# STM32WB05 register map
File version: 1.0
CPU: CM0+ r0p0, little endian, MPU, no FPU, 2 interrupt priority bits
Registers are 32-bit, read-write, reset 0x0 unless marked. A register's access mark holds for its fields unless they carry their own. Offsets are from the block's base; [hi:lo] are bit positions.

## USART
Base 0x41004000
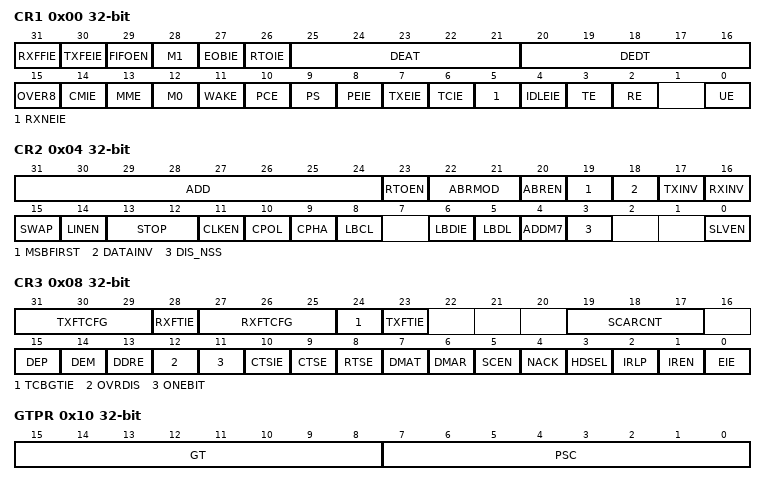
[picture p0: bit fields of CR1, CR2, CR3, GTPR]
0x00 CR1
  [31] RXFFIE — RXFFIE :RXFIFO Full interrupt enable This bit is set and cleared by software. -0: Interrupt is inhibited -1: An USART interrupt is generated when RXFF=1 in the USART_ISR register
    0=Disabled (Interrupt inhibited); 1=Enabled (USART interrupt generated when RXFF = 1 in the USART_ISR register)
  [30] TXFEIE — TXFEIE :TXFIFO empty interrupt enable This bit is set and cleared by software. -0: Interrupt is inhibited -1: An USART interrupt is generated when TXFE=1 in the USART_ISR register
    0=Disabled (Interrupt inhibited); 1=Enabled (USART interrupt generated when TXFE = 1 in the USART_ISR register)
  [29] FIFOEN — FIFOEN :FIFO mode enable This bit is set and cleared by software. -0: FIFO mode is disabled. -1: FIFO mode is enabled.
    0=Disabled (FIFO mode is disabled); 1=Enabled (FIFO mode is enabled)
  [28] M1 — Word length This bit, with bit 12 (M0) determine the word length. It is set or cleared by software. M[1:0] = 00: 1 Start bit, 8 Data bits, n Stop bit M[1:0] = 01: 1 Start bit, 9 Data bits, n Stop bit M[1:0] = 10: 1 Start bit, 7 Data bits, n Stop bit This bit can only be written when the USART is disabled (UE=0).s
    0=M0 (Use M0 to set the data bits); 1=Bit7 (1 start bit, 7 data bits, n stop bits)
  [27] EOBIE — EOBIE: End of Block interrupt enable This bit is set and cleared by software.
    0=Disabled (Interrupt is inhibited); 1=Enabled (A USART interrupt is generated when the EOBF flag is set in the ISR register)
  [26] RTOIE — RTOIE: Receiver timeout interrupt enable This bit is set and cleared by software. -0: Interrupt is inhibited -1: An USART interrupt is generated when the RTOF bit is set in the USART_ISR register
    0=Disabled (Interrupt is inhibited); 1=Enabled (An USART interrupt is generated when the RTOF bit is set in the ISR register)
  [25:21] DEAT — DEAT[4:0]: Driver Enable assertion time This 5-bit value defines the time between the activation of the DE (Driver Enable) signal and the beginning of the start bit. It is expressed in sample time units (1/8 or 1/16 bit time, depending on the oversampling rate). This bit field can only be written when the USART is disabled (UE=0).
  [20:16] DEDT — DEDT[4:0]: Driver Enable deassertion time This 5-bit value defines the time between the end of the last stop bit, in a transmitted message, and the de-activation of the DE (Driver Enable) signal. It is expressed in sample time units (1/8 or 1/16 bit time, depending on the oversampling rate). If the USART_TDR register is written during the DEDT time, the new data is transmitted only when the DEDT and DEAT times have both elapsed. This bit field can only be written when the USART is disabled (UE=0).
  [15] OVER8 — OVER8: Oversampling mode -0: Oversampling by 16 This bit can only be written when the USART is disabled (UE=0).
    0=Oversampling16 (Oversampling by 16); 1=Oversampling8 (Oversampling by 8)
  [14] CMIE — CMIE: Character match interrupt enable This bit is set and cleared by software. -0: Interrupt is inhibited -1: A USART interrupt is generated when the CMF bit is set in the USART_ISR register.
    0=Disabled (Interrupt is disabled); 1=Enabled (Interrupt is generated when the CMF bit is set in the ISR register)
  [13] MME — MME: Mute mode enable This bit activates the mute mode function of the USART. When set, the USART can switch between the active and mute modes, as defined by the WAKE bit. It is set and cleared by software. -0: Receiver in active mode permanently -1: Receiver can switch between mute mode and active mode
    0=Disabled (Receiver in active mode permanently); 1=Enabled (Receiver can switch between mute mode and active mode)
  [12] M0 — M0: Word length This bit, with bit 28 (M1) determine the word length. It is set or cleared by software. See Bit -28 (M1)description. This bit can only be written when the USART is disabled (UE=0).
    0=Bit8 (1 start bit, 8 data bits, n stop bits); 1=Bit9 (1 start bit, 9 data bits, n stop bits)
  [11] WAKE — WAKE: Receiver wakeup method This bit determines the USART wakeup method from Mute mode. It is set or cleared by software. -0: Idle line -1: Address mark This bit field can only be written when the USART is disabled (UE=0).
    0=Idle line; 1=Address mask
  [10] PCE — PCE: Parity control enable This bit selects the hardware parity control (generation and detection). When the parity control is enabled, the computed parity is inserted at the MSB position (9th bit if M=1; 8th bit if M=0) and parity is checked on the received data. This bit is set and cleared by software. Once it is set, PCE is active after the current byte (in reception and in transmission). -0: Parity control disabled -1: Parity control enabled This bit field can only be written when the USART is disabled (UE=0).
    0=Disabled (Parity control disabled); 1=Enabled (Parity control enabled)
  [9] PS — PS: Parity selection This bit selects the odd or even parity when the parity generation/detection is enabled (PCE bit set). It is set and cleared by software. The parity will be selected after the current byte. -0: Even parity -1: Odd parity This bit field can only be written when the USART is disabled (UE=0).
    0=Even parity; 1=Odd (Odd parity)
  [8] PEIE — PEIE: PE interrupt enable This bit is set and cleared by software. -0: Interrupt is inhibited -1: A USART interrupt is generated whenever PE=1 in the USART_ISR register
    0=Disabled (Interrupt is disabled); 1=Enabled (Interrupt is generated whenever PE=1 in the ISR register)
  [7] TXEIE — TXEIE/TXFNFIE: Transmit data regsiter empty/TXFIFO not full interrupt enable This bit is set and cleared by software. -0: Interrupt is inhibited -1: A USART interrupt is generated whenever TXE/TXFNF =1 in the USART_ISR register
    0=Disabled (Interrupt is disabled); 1=Enabled (Interrupt is generated whenever TXE=1 in the ISR register)
  [6] TCIE — TCIE: Transmission complete interrupt enable This bit is set and cleared by software. -0: Interrupt is inhibited -1: A USART interrupt is generated whenever TC=1 in the USART_ISR register
    0=Disabled (Interrupt is disabled); 1=Enabled (Interrupt is generated whenever TC=1 in the ISR register)
  [5] RXNEIE — RXNEIE/RXFNEIE: Receive data register not empty/RXFIFO not empty interrupt enable This bit is set and cleared by software. -0: Interrupt is inhibited -1: An USART interrupt is generated whenever ORE=1 or RXNE/RXFNE=1 in the USART_ISR register
    0=Disabled (Interrupt is disabled); 1=Enabled (Interrupt is generated whenever ORE=1 or RXNE=1 in the ISR register)
  [4] IDLEIE — IDLEIE: IDLE interrupt enable This bit is set and cleared by software. -0: Interrupt is inhibited -1: A USART interrupt is generated whenever IDLE=1 in the USART_ISR register
    0=Disabled (Interrupt is disabled); 1=Enabled (Interrupt is generated whenever IDLE=1 in the ISR register)
  [3] TE — TE: Transmitter enable This bit enables the transmitter. It is set and cleared by software. -0: Transmitter is disabled -1: Transmitter is enabled
    0=Disabled (Transmitter is disabled); 1=Enabled (Transmitter is enabled)
  [2] RE — RE: Receiver enable This bit enables the receiver. It is set and cleared by software. -0: Receiver is disabled -1: Receiver is enabled and begins searching for a start bit
    0=Disabled (Receiver is disabled); 1=Enabled (Receiver is enabled)
  [0] UE — UE: USART enable When this bit is cleared, the USART prescalers and outputs are stopped immediately, and current operations are discarded. The configuration of the USART is kept, but all the status flags, in the USART_ISR are reset. This bit is set and cleared by software. -0: USART prescaler and outputs disabled, low power mode -1: USART enabled
    0=Disabled (UART is disabled); 1=Enabled (UART is enabled)
0x04 CR2
  [31:24] ADD — ADD[7:0]: Address of the USART node This bit-field gives the address of the USART node or a character code to be recognized. This is used in multiprocessor communication during Mute mode or Stop mode, for wakeup with 7- bit address mark detection. The MSB of the character sent by the transmitter should be equal to 1. It may also be used for character detection during normal reception, Mute mode inactive (for example, end of block detection in ModBus protocol). In this case, the whole received character (8- bit) is compared to the ADD[7:0] value and CMF flag is set on match. This bit field can only be written when reception is disabled (RE = 0) or the USART is disabled (UE=0)
  [23] RTOEN — RTOEN: Receiver timeout enable This bit is set and cleared by software. -0: Receiver timeout feature disabled. -1: Receiver timeout feature enabled. When this feature is enabled, the RTOF flag in the USART_ISR register is set if the RX line is idle (no reception) for the duration programmed in the RTOR (receiver timeout register).
    0=Disabled (Receiver timeout feature disabled); 1=Enabled (Receiver timeout feature enabled)
  [22:21] ABRMOD — ABRMOD[1:0]: Auto baud rate mode These bits are set and cleared by software. -00: Measurement of the start bit is used to detect the baud rate. -01: Falling edge to falling edge measurement. (the received frame must start with a single bit = 1 -> Frame = Start10xxxxxx) -10: 0x7F frame detection. -11: 0x55 frame detection This bit field can only be written when ABREN = 0 or the USART is disabled (UE=0).
    0=Start (Measurement of the start bit is used to detect the baud rate); 1=Edge (Falling edge to falling edge measurement); 2=Frame7F (0x7F frame detection); 3=Frame55 (0x55 frame detection)
  [20] ABREN — ABREN: Auto baud rate enable This bit is set and cleared by software. -0: Auto baud rate detection is disabled. -1: Auto baud rate detection is enabled.
    0=Disabled (Auto baud rate detection is disabled); 1=Enabled (Auto baud rate detection is enabled)
  [19] MSBFIRST — MSBFIRST: Most significant bit first This bit is set and cleared by software. -0: data is transmitted/received with data bit 0 first, following the start bit. -1: data is transmitted/received with the MSB (bit 7/8) first, following the start bit. This bit field can only be written when the USART is disabled (UE=0).
    0=LSB (data is transmitted/received with data bit 0 first, following the start bit); 1=MSB (data is transmitted/received with MSB (bit 7/8/9) first, following the start bit)
  [18] DATAINV — DATAINV: Binary data inversion This bit is set and cleared by software. -0: Logical data from the data register are send/received in positive/direct logic. (1=H, 0=L) -1: Logical data from the data register are send/received in negative/inverse logic. (1=L, 0=H). The parity bit is also inverted. This bit field can only be written when the USART is disabled (UE=0).
    0=Positive (Logical data from the data register are send/received in positive/direct logic); 1=Negative (Logical data from the data register are send/received in negative/inverse logic)
  [17] TXINV — TXINV: TX pin active level inversion This bit is set and cleared by software. -0: TX pin signal works using the standard logic levels (VDD =1/idle, Gnd=0/mark) -1: TX pin signal values are inverted. ((VDD =0/mark, Gnd=1/idle). This allows the use of an external inverter on the TX line. This bit field can only be written when the USART is disabled (UE=0).
    0=Standard (TX pin signal works using the standard logic levels); 1=Inverted (TX pin signal values are inverted)
  [16] RXINV — RXINV: RX pin active level inversion This bit is set and cleared by software. -0: RX pin signal works using the standard logic levels (VDD =1/idle, Gnd=0/mark) -1: RX pin signal values are inverted. ((VDD =0/mark, Gnd=1/idle). This allows the use of an external inverter on the RX line. This bit field can only be written when the USART is disabled (UE=0).
    0=Standard (RX pin signal works using the standard logic levels); 1=Inverted (RX pin signal values are inverted)
  [15] SWAP — SWAP: Swap TX/RX pins This bit is set and cleared by software. -0: TX/RX pins are used as defined in standard pinout -1: The TX and RX pins functions are swapped. This allows to work in the case of a cross-wired connection to another UART. This bit field can only be written when the USART is disabled (UE=0).
    0=Standard (TX/RX pins are used as defined in standard pinout); 1=Swapped (The TX and RX pins functions are swapped)
  [14] LINEN — LINEN: LIN mode enable This bit is set and cleared by software. -0: LIN mode disabled -1: LIN mode enabled The LIN mode enables the capability to send LIN Synch Breaks (13 low bits) using the SBKRQ bit in the USART_CR1 register, and to detect LIN Sync breaks. This bit field can only be written when the USART is disabled (UE=0).
    0=Disabled (LIN mode disabled); 1=Enabled (LIN mode enabled)
  [13:12] STOP — STOP[1:0]: STOP bits These bits are used for programming the stop bits. -00: 1 stop bit -01: 0.5 stop bit. -10: 2 stop bits -11: 1.5 stop bits This bit field can only be written when the USART is disabled (UE=0).
    0=1 stop bit; 1=Stop0p5 (0.5 stop bit); 2=2 stop bit; 3=Stop1p5 (1.5 stop bit)
  [11] CLKEN — CLKEN: Clock enable This bit allows the user to enable the SCLK pin. -0: SCLK pin disabled -1: SCLK pin enabled This bit can only be written when the USART is disabled (UE=0). Note: If neither synchronous mode nor Smartcard mode is supported, this bit is reserved and forced by hardware to 0'. Please refer to Section 23.4: USART implementation on page 483. Note: In Smartcard mode, in order to provide correctly the SCLK clock to the smartcard, the steps below must be respected: - UE = 0 - SCEN = 1 - GTPR configuration - CLKEN= 1 - UE = 1
    0=Disabled (CK pin disabled); 1=Enabled (CK pin enabled)
  [10] CPOL — CPOL: Clock polarity This bit allows the user to select the polarity of the clock output on the SCLK pin in synchronous mode. It works in conjunction with the CPHA bit to produce the desired clock/data relationship -0: Steady low value on SCLK pin outside transmission window -1: Steady high value on SCLK pin outside transmission window This bit can only be written when the USART is disabled (UE=0).
    0=Low (Steady low value on CK pin outside transmission window); 1=High (Steady high value on CK pin outside transmission window)
  [9] CPHA — CPHA: Clock phase This bit is used to select the phase of the clock output on the SCLK pin in synchronous mode. It works in conjunction with the CPOL bit to produce the desired clock/data relationship (see Figure 137 and Figure 138) -0: The first clock transition is the first data capture edge -1: The second clock transition is the first data capture edge This bit can only be written when the USART is disabled (UE=0).
    0=First (The first clock transition is the first data capture edge); 1=Second (The second clock transition is the first data capture edge)
  [8] LBCL — LBCL: Last bit clock pulse This bit is used to select whether the clock pulse associated with the last data bit transmitted (MSB) has to be output on the SCLK pin in synchronous mode. -0: The clock pulse of the last data bit is not output to the SCLK pin -1: The clock pulse of the last data bit is output to the SCLK pin Caution: The last bit is the 7th or 8th or 9th data bit transmitted depending on the 7 or 8 or 9 bit format selected by the M bit in the USART_CR1 register. This bit can only be written when the USART is disabled (UE=0).
    0=NotOutput (The clock pulse of the last data bit is not output to the CK pin); 1=Output (The clock pulse of the last data bit is output to the CK pin)
  [6] LBDIE — LBDIE: LIN break detection interrupt enable Break interrupt mask (break detection using break delimiter). -0: Interrupt is inhibited -1: An interrupt is generated whenever LBDF=1 in the USART_ISR register
    0=Disabled (Interrupt is inhibited); 1=Enabled (An interrupt is generated whenever LBDF=1 in the ISR register)
  [5] LBDL — LBDL: LIN break detection length This bit is for selection between 11 bit or 10 bit break detection. -0: 10-bit break detection -1: 11-bit break detection This bit can only be written when the USART is disabled (UE=0).
    0=Bit10 (10-bit break detection); 1=Bit11 (11-bit break detection)
  [4] ADDM7 — ADDM7:7-bit Address Detection/4-bit Address Detection This bit is for selection between 4-bit address detection or 7-bit address detection. -0: 4-bit address detection -1: 7-bit address detection (in 8-bit data mode) This bit can only be written when the USART is disabled (UE=0)
    0=Bit4 (4-bit address detection); 1=Bit7 (7-bit address detection)
  [3] DIS_NSS — DIS_NSS When the DSI_NSS bit is set, the NSS pin input will be ignored. -0: SPI slave selection depends on NSS input pin. -1: SPI slave will be always selected and NSS input pin will be ignored. Note: When SPI slave mode is not supported, this bit is reserved and must be kept at reset value
    0=Disabled (SPI slave selection depends on NSS input pin); 1=Enabled (SPI slave is always selected and NSS input pin is ignored)
  [0] SLVEN — SLVEN: Synchronous Slave mode enable When the SLVEN bit is set, the synchronous slave mode is enabled. -0: Slave mode disabled. -1: Slave mode enabled. Note: When SPI slave mode is not supported, this bit is reserved and must be kept at reset value
    0=Disabled (Slave mode disabled); 1=Enabled (Slave mode enabled)
0x08 CR3
  [31:29] TXFTCFG — TXFTCFG: TXFIFO threshold configuration -000:TXFIFO reaches 1/8 of its depth. -001:TXFIFO reaches 1/4 of its depth. -010:TXFIFO reaches 1/2 of its depth. -011:TXFIFO reaches 3/4 of its depth. -100:TXFIFO reaches 7/8 of its depth. -101:TXFIFO becomes empty. Remaining combinations: Reserved.
    0=Depth_1_8 (TXFIFO reaches 1/8 of its depth); 1=Depth_1_4 (TXFIFO reaches 1/4 of its depth); 2=Depth_1_2 (TXFIFO reaches 1/2 of its depth); 3=Depth_3_4 (TXFIFO reaches 3/4 of its depth); 4=Depth_7_8 (TXFIFO reaches 7/8 of its depth); 5=Empty (TXFIFO becomes empty)
  [28] RXFTIE — RXFTIE: RXFIFO threshold interrupt enable This bit is set and cleared by software. -0: Interrupt is inhibited -1: An USART interrupt is generated when Receive FIFO reaches the threshold programmed in RXFTCFG.
    0=Disabled (Interrupt inhibited); 1=Enabled (USART interrupt generated when Receive FIFO reaches the threshold programmed in RXFTCFG)
  [27:25] RXFTCFG — RXFTCFG: Receive FIFO threshold configuration -000:Receive FIFO reaches 1/8 of its depth. -001:Receive FIFO reaches 1/4 of its depth. -010:Receive FIFO reaches 1/2 of its depth. -011:Receive FIFO reaches 3/4 of its depth. -100:Receive FIFO reaches 7/8 of its depth. -101:Receive FIFO becomes full. Remaining combinations: Reserved.
    0=Depth_1_8 (RXFIFO reaches 1/8 of its depth); 1=Depth_1_4 (RXFIFO reaches 1/4 of its depth); 2=Depth_1_2 (RXFIFO reaches 1/2 of its depth); 3=Depth_3_4 (RXFIFO reaches 3/4 of its depth); 4=Depth_7_8 (RXFIFO reaches 7/8 of its depth); 5=Full (RXFIFO becomes full)
  [24] TCBGTIE — TCBGTIE: Transmission Complete before guard time, interrupt enable This bit is set and cleared by software. -0: Interrupt is inhibited -1: An USART interrupt is generated whenever TCBGT=1 in the USARTx_ISR register
    0=Disabled (Interrupt inhibited); 1=Enabled (USART interrupt generated whenever TCBGT=1 in the USART_ISR register)
  [23] TXFTIE — TXFTIE: TXFIFO threshold interrupt enable This bit is set and cleared by software. -0: Interrupt is inhibited -1: An USART interrupt is generated when TXFIFO reaches the threshold programmed in TXFTCFG.
    0=Disabled (Interrupt inhibited); 1=Enabled (USART interrupt generated when Transmit FIFO reaches the threshold programmed in TXFTCFG)
  [19:17] SCARCNT — SCARCNT[2:0]: Smartcard auto-retry count This bit-field specifies the number of retries in transmit and receive, in Smartcard mode. In transmission mode, it specifies the number of automatic retransmission retries, before generating a transmission error (FE bit set). In reception mode, it specifies the number or erroneous reception trials, before generating a reception error (RXNE/RXFNE and PE bits set). This bit field must be programmed only when the USART is disabled (UE=0). When the USART is enabled (UE=1), this bit field may only be written to 0x0, in order to stop retransmission. -0x0: retransmission disabled - No automatic retransmission in transmit mode. -0x1 to 0x7: number of automatic retransmission attempts (before signaling error)
  [15] DEP — DEP: Driver enable polarity selection -0: DE signal is active high. -1: DE signal is active low. This bit can only be written when the USART is disabled (UE=0).
    0=High (DE signal is active high); 1=Low (DE signal is active low)
  [14] DEM — DEM: Driver enable mode This bit allows the user to activate the external transceiver control, through the DE signal. -0: DE function is disabled. -1: DE function is enabled. The DE signal is output on the RTS pin. This bit can only be written when the USART is disabled (UE=0).
    0=Disabled (DE function is disabled); 1=Enabled (The DE signal is output on the RTS pin)
  [13] DDRE — DDRE: DMA Disable on Reception Error -0: DMA is not disabled in case of reception error. The corresponding error flag is set but RXNE is kept 0 preventing from overrun. As a consequence, the DMA request is not asserted, so the erroneous data is not transferred (no DMA request), but next correct received data will be transferred. (used for Smartcard mode) -1: DMA is disabled following a reception error. The corresponding error flag is set, as well as RXNE. The DMA request is masked until the error flag is cleared. This means that the software must first disable the DMA request (DMAR = 0) or clear RXNE(RXFNE is case FIFO mode is enabled) before clearing the error flag. This bit can only be written when the USART is disabled (UE=0).
    0=NotDisabled (DMA is not disabled in case of reception error); 1=Disabled (DMA is disabled following a reception error)
  [12] OVRDIS — OVRDIS: Overrun Disable This bit is used to disable the receive overrun detection. -0: Overrun Error Flag, ORE, is set when received data is not read before receiving new data. -1: Overrun functionality is disabled. If new data is received while the RXNE flag is still set the ORE flag is not set and the new received data overwrites the previous content of the USART_RDR register. When FIFO mode is enabled, the RXFIFO will be bypassed and data will be written directly in USARTx_RDR register. Even when FIFO management is enabled, the RXNE flag is to be used. This bit can only be written when the USART is disabled (UE=0).
    0=Enabled (Overrun Error Flag, ORE, is set when received data is not read before receiving new data); 1=Disabled (Overrun functionality is disabled. If new data is received while the RXNE flag is still set the ORE flag is not set and the new received data overwrites the previous content of the RDR register)
  [11] ONEBIT — ONEBIT: One sample bit method enable This bit allows the user to select the sample method. When the one sample bit method is selected the noise detection flag (NF) is disabled. -0: Three sample bit method -1: One sample bit method This bit can only be written when the USART is disabled (UE=0).
    0=Sample3 (Three sample bit method); 1=Sample1 (One sample bit method)
  [10] CTSIE — CTSIE: CTS interrupt enable -0: Interrupt is inhibited -1: An interrupt is generated whenever CTSIF=1 in the USART_ISR register
    0=Disabled (Interrupt is inhibited); 1=Enabled (An interrupt is generated whenever CTSIF=1 in the ISR register)
  [9] CTSE — CTSE: CTS enable -0: CTS hardware flow control disabled -1: CTS mode enabled, data is only transmitted when the nCTS input is asserted (tied to 0). If the nCTS input is deasserted while data is being transmitted, then the transmission is completed before stopping. If data is written into the data register while nCTS is asserted, the transmission is postponed until nCTS is asserted. This bit can only be written when the USART is disabled (UE=0)
    0=Disabled (CTS hardware flow control disabled); 1=Enabled (CTS mode enabled, data is only transmitted when the CTS input is asserted)
  [8] RTSE — RTSE: RTS enable -0: RTS hardware flow control disabled -1: RTS output enabled, data is only requested when there is space in the receive buffer. The transmission of data is expected to cease after the current character has been transmitted. The nRTS output is asserted (pulled to 0) when data can be received. This bit can only be written when the USART is disabled (UE=0).
    0=Disabled (RTS hardware flow control disabled); 1=Enabled (RTS output enabled, data is only requested when there is space in the receive buffer)
  [7] DMAT — DMAT: DMA enable transmitter This bit is set/reset by software -1: DMA mode is enabled for transmission -0: DMA mode is disabled for transmission
    0=Disabled (DMA mode is disabled for transmission); 1=Enabled (DMA mode is enabled for transmission)
  [6] DMAR — DMAR: DMA enable receiver This bit is set/reset by software -1: DMA mode is enabled for reception -0: DMA mode is disabled for reception
    0=Disabled (DMA mode is disabled for reception); 1=Enabled (DMA mode is enabled for reception)
  [5] SCEN — SCEN: Smartcard mode enable This bit is used for enabling Smartcard mode. -0: Smartcard Mode disabled -1: Smartcard Mode enabled This bit field can only be written when the USART is disabled (UE=0).
    0=Disabled (Smartcard Mode disabled); 1=Enabled (Smartcard Mode enabled)
  [4] NACK — NACK: Smartcard NACK enable -0: NACK transmission in case of parity error is disabled -1: NACK transmission during parity error is enabled This bit field can only be written when the USART is disabled (UE=0).
    0=Disabled (NACK transmission in case of parity error is disabled); 1=Enabled (NACK transmission during parity error is enabled)
  [3] HDSEL — HDSEL: Half-duplex selection Selection of Single-wire Half-duplex mode -0: Half duplex mode is not selected -1: Half duplex mode is selected This bit can only be written when the USART is disabled (UE=0).
    0=NotSelected (Half duplex mode is not selected); 1=Selected (Half duplex mode is selected)
  [2] IRLP — IRLP: IrDA low-power This bit is used for selecting between normal and low-power IrDA modes -0: Normal mode -1: Low-power mode This bit can only be written when the USART is disabled (UE=0).
    0=Normal mode; 1=Low-power mode
  [1] IREN — IREN: IrDA mode enable This bit is set and cleared by software. -0: IrDA disabled -1: IrDA enabled This bit can only be written when the USART is disabled (UE=0).
    0=Disabled (IrDA disabled); 1=Enabled (IrDA enabled)
  [0] EIE — EIE: Error interrupt enable Error Interrupt Enable Bit is required to enable interrupt generation in case of a framing error, overrun error noise flag or SPI slave underrun error (FE=1 or ORE=1 or NF=1or UDR = 1 in the USART_ISR register). -0: Interrupt is inhibited -1: An interrupt is generated when FE=1 or ORE=1 or NF=1 or UDR = 1 (in SPI slave mode) in the USART_ISR register.
    0=Disabled (Interrupt is inhibited); 1=Enabled (An interrupt is generated when FE=1 or ORE=1 or NF=1 in the ISR register)
0x0C BRR
  [15:0] BRR — BRR[15:4] BRR[15:4] = USARTDIV[15:4]BRR[3:0] When OVER8 = 0, BRR[3:0] = USARTDIV[3:0]. When OVER8 = 1: BRR[2:0] = USARTDIV[3:0] shifted 1 bit to the right. BRR[3] must be kept cleared
0x10 GTPR
  [15:8] GT — GT[7:0]: Guard time value This bit-field is used to program the Guard time value in terms of number of baud clock periods. This is used in Smartcard mode. The Transmission Complete flag is set after this guard time value. This bit field can only be written when the USART is disabled (UE=0).
  [7:0] PSC — PSC[7:0]: Prescaler value In IrDA Low-power and normal IrDA mode: PSC[7:0] = IrDA Normal and Low-Power Baud Rate Used for programming the prescaler for dividing the USART source clock to achieve the lowpower frequency: The source clock is divided by the value given in the register (8 significant bits): -00000000: Reserved - do not program this value -00000001: divides the source clock by 1 -00000010: divides the source clock by 2 ... In Smartcard mode: PSC[4:0]: Prescaler value Used for programming the prescaler for dividing the USART source clock to provide the Smartcard clock. The value given in the register (5 significant bits) is multiplied by 2 to give the division factor of the source clock frequency: -00000: Reserved - do not program this value -00001: divides the source clock by 2 -00010: divides the source clock by 4 -00011: divides the source clock by 6 ... This bit field can only be written when the USART is disabled (UE=0).
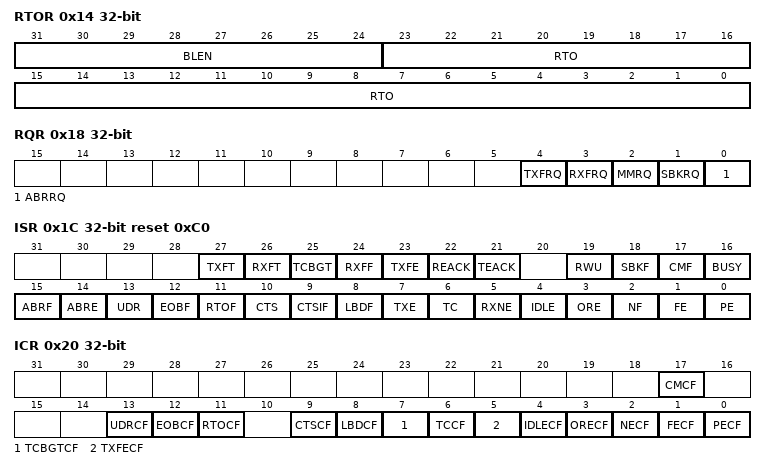
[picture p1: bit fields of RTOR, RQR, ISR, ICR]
0x14 RTOR
  [31:24] BLEN — BLEN[7:0]: Block Length This bit-field gives the Block length in Smartcard T=1 Reception. Its value equals the number of information characters + the length of the Epilogue Field (1-LEC/2-CRC) - 1. Examples: BLEN = 0 -> 0 information characters + LEC BLEN = 1 -> 0 information characters + CRC BLEN = 255 -> 254 information characters + CRC (total 256 characters)) In Smartcard mode, the Block length counter is reset when TXE=0 (TXFE = 0 in case FIFO mode is enabled). This bit-field can be used also in other modes. In this case, the Block length counter is reset when RE=0 (receiver disabled) and/or when the EOBCF bit is written to 1.
  [23:0] RTO — RTO[23:0]: Receiver timeout value This bit-field gives the Receiver timeout value in terms of number of baud clocks. In standard mode, the RTOF flag is set if, after the last received character, no new start bit is detected for more than the RTO value. In Smartcard mode, this value is used to implement the CWT and BWT. See Smartcard chapter for more details. In the standard, the CWT/BWT measurement is done starting from the Start Bit of the last received character.
0x18 RQR
  [4] TXFRQ wo — TXFRQ: Transmit data flush request When FIFO mode is disabled, Writing 1 to this bit sets the TXE flag. This allows to discard the transmit data. This bit must be used only in Smartcard mode, when data has not been sent due to errors (NACK) and the FE flag is active in the USART_ISR register. If the USART does not support Smartcard mode, this bit is reserved and forced by hardware to 0' When FIFO is enabled, TXFRQ bit is set to flush the whole FIFO . This will set the flag TXFE (Transmit FIFO empty, bit 23 in the USART_ISR register). Flushing the Transmit FIFO is supported in both UART and Smartcard modes.
    1=Discard (Set the TXE flags. This allows to discard the transmit data)
  [3] RXFRQ wo — RXFRQ: Receive data flush request Writing 1 to this bit empties the entire receive FIFO i.e. clears the bit RXFNE. This allows to discard the received data without reading them, and avoid an overrun condition.
    1=Discard (clears the RXNE flag. This allows to discard the received data without reading it, and avoid an overrun condition)
  [2] MMRQ wo — MMRQ: Mute mode request Writing 1 to this bit puts the USART in mute mode and resets the RWU flag.
    1=Mute (Puts the USART in mute mode and sets the RWU flag)
  [1] SBKRQ wo — SBKRQ: Send break request Writing 1 to this bit sets the SBKF flag and request to send a BREAK on the line, as soon as the transmit machine is available.
    1=Break (sets the SBKF flag and request to send a BREAK on the line, as soon as the transmit machine is available)
  [0] ABRRQ wo — ABRRQ: Auto baud rate request Writing 1 to this bit resets the ABRF flag in the USART_ISR and request an automatic baud rate measurement on the next received data frame.
    1=Request (resets the ABRF flag in the USART_ISR and request an automatic baud rate measurement on the next received data frame)
0x1C ISR ro reset 0xC0
  [27] TXFT — TXFT: TXFIFO threshold flag This bit is set by hardware when the TXFIFO reaches the programmed threshold in TXFTCFG in USARTx_CR3 register i.e. the TXFIFO contains TXFTCFG empty locations. An interrupt is generated if the TXFTIE bit =1 (bit 31) in the USART_CR3 register. -0: TXFIFO doesn't reach the programmed threshold. -1: TXFIFO reached the programmed threshold
    0=NotReached (TXFIFO does not reach the programmed threshold.); 1=Reached (TXFIFO reached the programmed threshold.)
  [26] RXFT — RXFT: RXFIFO threshold flag This bit is set by hardware when the programmed threshold in RXFTCFG in USARTx_CR3 register is reached. This means that there are (RXFTCFG - 1) data in the Receive FIFO and one data in the USART_RDR register. An interrupt is generated if the RXFTIE bit =1 (bit 27) in the USART_CR3 register. -0: Receive FIFO doesn't reach the programmed threshold. -1: Receive FIFO reached the programmed threshold
    0=NotReached (Receive FIFO does not reach the programmed threshold.); 1=Reached (Receive FIFO reached the programmed threshold.)
  [25] TCBGT — TCBGT: Transmission complete before guard time flagl This bit indicates when the last data written in the USART_TDR has been transmitted correctly out of the shift register . It is set by hardware in Smartcard mode, if the transmission of a frame containing data is complete and if there is no NACK from the smartcard. An interrupt is generated if TCBGTIE=1 in the USART_CR3 register. It is cleared by software, writing 1 to the TCBGTCF in the USART_ICR register or by a write to the USART_TDR register. -0: Transmission is not complete or transmission is complete unsuccessfuly (i.e. a NACK is received from the card) -1: Transmission is complete successfully (before Guard time completion and there is no NACK from the smart card).
    0=NotCompleted (Transmission is not complete or transmission is complete unsuccessfully (i.e. a NACK is received from the card)); 1=Completed (Transmission is complete successfully (before Guard time completion and there is no NACK from the smart card))
  [24] RXFF — RXFF: RXFIFO Full This bit is set by hardware when RXFIFO is Full. An interrupt is generated if the RXFFIE bit =1 in the USART_CR1 register. -0: RXFIFO is not Full. -1: RXFIFO is Full.
    0=NotFull (RXFIFO not full.); 1=Full (RXFIFO Full.)
  [23] TXFE — TXFE: TXFIFO Empty This bit is set by hardware when TXFIFO is Empty. When the TXFIFO contains at least one data, this flag is cleared. The TXFE flag can also be set by writing 1 to the bit TXFRQ (bit 4) in the USART_RQR register. An interrupt is generated if the TXFEIE bit =1 (bit 30) in the USART_CR1 register. -0: TXFIFO is not empty. -1: TXFIFO is empty.
    0=NotEmpty (TXFIFO not empty.); 1=Empty (TXFIFO empty.)
  [22] REACK — REACK: Receive enable acknowledge flag This bit is set/reset by hardware, when the Receive Enable value is taken into account by the USART. It can be used to verify that the USART is ready for reception before entering Stop mode.
  [21] TEACK — TEACK: Transmit enable acknowledge flag This bit is set/reset by hardware, when the Transmit Enable value is taken into account by the USART. It can be used when an idle frame request is generated by writing TE=0, followed by TE=1 in the USART_CR1 register, in order to respect the TE=0 minimum period.
  [19] RWU — RWU: Receiver wakeup from Mute mode This bit indicates if the USART is in mute mode. It is cleared/set by hardware when a wakeup/mute sequence is recognized. The mute mode control sequence (address or IDLE) is selected by the WAKE bit in the USART_CR1 register. When wakeup on IDLE mode is selected, this bit can only be set by software, writing 1 to the MMRQ bit in the USART_RQR register. -0: Receiver in active mode -1: Receiver in mute mode
  [18] SBKF — SBKF: Send break flag This bit indicates that a send break character was requested. It is set by software, by writing 1 to the SBKRQ bit in the USART_CR3 register. It is automatically reset by hardware during the stop bit of break transmission. -0: No break character is transmitted -1: Break character will be transmitted
    0=No break character transmitted; 1=Break character transmitted
  [17] CMF — CMF: Character match flag This bit is set by hardware, when a the character defined by ADD[7:0] is received. It is cleared by software, writing 1 to the CMCF in the USART_ICR register. An interrupt is generated if CMIE=1in the USART_CR1 register. -0: No Character match detected -1: Character Match detected
    0=NoMatch (No Character match detected); 1=Match (Character match detected)
  [16] BUSY — BUSY: Busy flag This bit is set and reset by hardware. It is active when a communication is ongoing on the RX line (successful start bit detected). It is reset at the end of the reception (successful or not). -0: USART is idle (no reception) -1: Reception on going
    0=Idle (USART is idle (no reception)); 1=Busy (Reception on going)
  [15] ABRF — ABRF: Auto baud rate flag This bit is set by hardware when the automatic baud rate has been set (RXNE will also be set, generating an interrupt if RXNEIE = 1) or when the auto baud rate operation was completed without success (ABRE=1) (ABRE, RXNE and FE are also set in this case) It is cleared by software, in order to request a new auto baud rate detection, by writing 1 to the ABRRQ in the USART_RQR register.
  [14] ABRE — ABRE: Auto baud rate error This bit is set by hardware if the baud rate measurement failed (baud rate out of range or character comparison failed) It is cleared by software, by writing 1 to the ABRRQ bit in the USART_CR3 register
  [13] UDR — UDR: SPI slave underrun error flag In slave transmission mode, this flag is set when the first clock for data transmission appears while the software has not yet loaded any value into USARTx_DR. -0: No underrun error -1: underrun error
    0=No underrun error; 1=underrun error
  [12] EOBF — EOBF: End of block flag This bit is set by hardware when a complete block has been received (for example T=1 Smartcard mode). The detection is done when the number of received bytes (from the start of the block, including the prologue) is equal or greater than BLEN + 4. An interrupt is generated if the EOBIE=1 in the USART_CR2 register. It is cleared by software, writing 1 to the EOBCF in the USART_ICR register. -0: End of Block not reached -1: End of Block (number of characters) reached
    0=NotReached (End of Block not reached); 1=Reached (End of Block (number of characters) reached)
  [11] RTOF — RTOF: Receiver timeout This bit is set by hardware when the timeout value, programmed in the RTOR register has lapsed, without any communication. It is cleared by software, writing 1 to the RTOCF bit in the USART_ICR register. An interrupt is generated if RTOIE=1 in the USART_CR2 register. In Smartcard mode, the timeout corresponds to the CWT or BWT timings. -0: Timeout value not reached -1: Timeout value reached without any data reception
    0=NotReached (Timeout value not reached); 1=Reached (Timeout value reached without any data reception)
  [10] CTS — CTS: CTS flag This bit is set/reset by hardware. It is an inverted copy of the status of the nCTS input pin. -0: nCTS line set -1: nCTS line reset
    0=Set (CTS line set); 1=Reset (CTS line reset)
  [9] CTSIF — CTSIF: CTS interrupt flag This bit is set by hardware when the nCTS input toggles, if the CTSE bit is set. It is cleared by software, by writing 1 to the CTSCF bit in the USART_ICR register. An interrupt is generated if CTSIE=1 in the USART_CR3 register. -0: No change occurred on the nCTS status line -1: A change occurred on the nCTS status line
    0=NotChanged (No change occurred on the CTS status line); 1=Changed (A change occurred on the CTS status line)
  [8] LBDF — LBDF: LIN break detection flag This bit is set by hardware when the LIN break is detected. It is cleared by software, by writing 1 to the LBDCF in the USART_ICR. An interrupt is generated if LBDIE = 1 in the USART_CR2 register. -0: LIN Break not detected -1: LIN break detected
    0=NotDetected (LIN break not detected); 1=Detected (LIN break detected)
  [7] TXE — TXE/TXFNF: Transmit data register empty/TXFIFO not full When FIFO mode is disabled, TXE is set by hardware when the content of the USARTx_TDR register has been transferred into the shift register. It is cleared by a write to the USARTx_TDR register. The TXE flag can also be set by writing 1 to the TXFRQ in the USART_RQR register, in order to discard the data (only in Smartcard T=0 mode, in case of transmission failure). When FIFO mode is enabled, TXFNF is set by hardware when TXFIFO is not full, and so data can be written in the USART_TDR. Every write in the USART_TDR places the data in the TXFIFO. This flag remains set until the TXFIFO is full. When the TXFIFO is full, this flag is cleared indicating that data can not be written into the USART_TDR. Note: The TXFNF is kept reset during the flush request until TXFIFO is empty . After sending the flush request (by setting TXFRQ bit), the flag TXFNF should be checked prior to writing in TXFIFO. (TXFNF and TXFE will be set at the same time). An interrupt is generated if the TXEIE/TXFNFIE bit =1 in the USART_CR1 register. -0: Data register is full/Transmit FIFO is full. -1: Data register/Transmit FIFO is not full
    0=Full (Transmit FIFO is full); 1=NotFull (Transmit FIFO is not full)
  [6] TC — TC: Transmission complete This bit indicates when the last data written in the USART_TDR has been transmitted out of the shift register. It is set by hardware if the transmission of a frame containing data is complete and if TXE/TXFE is set. An interrupt is generated if TCIE=1 in the USART_CR1 register. It is cleared by software, writing 1 to the TCCF in the USART_ICR register or by a write to the USART_TDR register. An interrupt is generated if TCIE=1 in the USART_CR1 register. -0: Transmission is not complete -1: Transmission is complete
    0=TxNotComplete (Transmission is not complete); 1=TxComplete (Transmission is complete)
  [5] RXNE — RXNE/RXFNE:Read data register not empty/RXFIFO not empty RXNE bit is set by hardware when the content of the USARTx_RDR shift register has been transferred to the USARTx_RDR register. It is cleared by a read to the USARTx_RDR register. The RXNE flag can also be cleared by writing 1 to the RXFRQ in the USARTx_RQR register. RXFNE bit is set by hardware when the RXFIFO is not empty, and so data can be read from the USART_RDR register. Every read of the USART_RDR frees a location in the RXFIFO. It is cleared when the RXFIFO is empty. The RXNE/RXFNE flag can also be cleared by writing 1 to the RXFRQ in the USART_RQR register. An interrupt is generated if RXNEIE/RXFNEIE=1 in the USART_CR1 register. -0: Data is not received -1: Received data is ready to be read.
    0=NoData (Data is not received); 1=DataReady (Received data is ready to be read)
  [4] IDLE — IDLE: Idle line detected This bit is set by hardware when an Idle Line is detected. An interrupt is generated if IDLEIE=1 in the USART_CR1 register. It is cleared by software, writing 1 to the IDLECF in the USART_ICR register. -0: No Idle line is detected -1: Idle line is detected
    0=No Idle Line is detected; 1=Idle Line is detected
  [3] ORE — ORE: Overrun error This bit is set by hardware when the data currently being received in the shift register is ready to be transferred into the USARTx_RDR register while RXNE=1 (RXFF = 1 in case FIFO mode is enabled) . It is cleared by a software, writing 1 to the ORECF, in the USARTx_ICR register. An interrupt is generated if RXNEIE/ RXFNEIE=1 or EIE = 1 in the USARTx_CR1 register. -0: No overrun error -1: Overrun error is detected
    0=No Overrun error; 1=Overrun error is detected
  [2] NF — NF: START bit Noise detection flag This bit is set by hardware when noise is detected on a received frame. It is cleared by software, writing 1 to the NFCF bit in the USART_ICR register. -0: No noise is detected -1: Noise is detected
    0=No noise is detected; 1=Noise is detected
  [1] FE — FE: Framing error This bit is set by hardware when a de-synchronization, excessive noise or a break character is detected. It is cleared by software, writing 1 to the FECF bit in the USART_ICR register. In Smartcard mode, in transmission, this bit is set when the maximum number of transmit attempts is reached without success (the card NACKs the data frame). An interrupt is generated if EIE = 1 in the USART_CR1 register. -0: No Framing error is detected -1: Framing error or break character is detected
    0=NoError (No Framing error is detected); 1=Error (Framing error or break character is detected)
  [0] PE — PE: Parity error This bit is set by hardware when a parity error occurs in receiver mode. It is cleared by software, writing 1 to the PECF in the USART_ICR register. An interrupt is generated if PEIE = 1 in the USART_CR1 register. -0: No parity error -1: Parity error
    0=NoError (No parity error); 1=Error (Parity error)
0x20 ICR
  [17] CMCF wo write-1-clears — CMCF: Character match clear flag Writing 1 to this bit clears the CMF flag in the USART_ISR register
    1=Clears the CMF flag in the ISR register
  [13] UDRCF wo write-1-clears — UDRCF:SPI slave underrun clear flag Writing 1 to this bit clears the UDRF flag in the USART_ISR register
    1=Clear the UDR flag in the ISR register
  [12] EOBCF wo write-1-clears — EOBCF: End of block clear flag Writing 1 to this bit clears the EOBF flag in the USART_ISR register
    1=Clears the EOBF flag in the ISR register
  [11] RTOCF wo write-1-clears — RTOCF: Receiver timeout clear flag Writing 1 to this bit clears the RTOF flag in the USART_ISR register.
    1=Clears the RTOF flag in the ISR register
  [9] CTSCF wo write-1-clears — CTSCF: CTS clear flag Writing 1 to this bit clears the CTSIF flag in the USART_ISR register
    1=Clears the CTSIF flag in the ISR register
  [8] LBDCF wo write-1-clears — LBDCF: LIN break detection clear flag Writing 1 to this bit clears the LBDF flag in the USART_ISR register.
    1=Clears the LBDF flag in the ISR register
  [7] TCBGTCF wo write-1-clears — TCBGTCF: Transmission complete before Guard time clear flag Writing 1 to this bit clears the TCBGT flag in the USART_ISR register.
    1=Clear the TCBGT flag in the ISR register
  [6] TCCF wo write-1-clears — TCCF: Transmission complete clear flag Writing 1 to this bit clears the TC flag in the USART_ISR register
    1=Clears the TC flag in the ISR register
  [5] TXFECF wo write-1-clears — TXFECF: TXFIFO empty clear flag Writing 1 to this bit clears the TXFE flag in the USART_ISR register
    1=Clear the TXFE flag in the ISR register
  [4] IDLECF wo write-1-clears — IDLECF: Idle line detected clear flag Writing 1 to this bit clears the IDLE flag in the USART_ISR register.
    1=Clears the IDLE flag in the ISR register
  [3] ORECF wo write-1-clears — ORECF: Overrun error clear flag Writing 1 to this bit clears the ORE flag in the USART_ISR register.
    1=Clears the ORE flag in the ISR register
  [2] NECF wo write-1-clears — NECF: Noise detected clear flag Writing 1 to this bit clears the NF flag in the USART_ISR register.
    1=Clears the NF flag in the ISR register
  [1] FECF wo write-1-clears — FECF: Framing error clear flag Writing 1 to this bit clears the FE flag in the USART_ISR register
    1=Clears the FE flag in the ISR register
  [0] PECF wo write-1-clears — PECF: Parity error clear flag Writing 1 to this bit clears the PE flag in the USART_ISR register.
    1=Clears the PE flag in the ISR register
0x24 RDR ro
  [8:0] RDR — RDR[8:0]: Receive data value Contains the received data character. The RDR register provides the parallel interface between the input shift register and the internal bus (see Figure 124). When receiving with the parity enabled, the value read in the MSB bit is the received parity bit.
0x28 TDR
  [8:0] TDR — TDR[8:0]: Transmit data value Contains the data character to be transmitted. The USARTx_TDR register provides the parallel interface between the internal bus and the output shift register (see Figure 124). When transmitting with the parity enabled (PCE bit set to 1 in the USART_CR1 register), the value written in the MSB (bit 7 or bit 8 depending on the data length) has no effect because it is replaced by the parity. Note: This register must be written only when TXE/TXFNF=1.
0x2C PRESC
  [3:0] PRESCALER — PRESCALER[3:0]: Clock prescaler The USART input clock can be divided by a prescaler: -0000: input clock not divided -0001: input clock divided by 2 -0010: input clock divided by 4 -0011: input clock divided by 6 -0100: input clock divided by 8 -0101: input clock divided by 10 -0110: input clock divided by 12 -0111: input clock divided by 16 -1000: input clock divided by 32 -1001: input clock divided by 64 -1010: input clock divided by 128 -1011: input clock divided by 256 Remaing combinations: Reserved. Note: When PRESCALER is programmed with a value different of the allowed ones, programmed prescaler value will be '1011' i.e. input clock divided by 256
    0=Div1 (Input clock divided by 1); 1=Div2 (Input clock divided by 2); 2=Div4 (Input clock divided by 4); 3=Div6 (Input clock divided by 6); 4=Div8 (Input clock divided by 8); 5=Div10 (Input clock divided by 10); 6=Div12 (Input clock divided by 12); 7=Div16 (Input clock divided by 16); 8=Div32 (Input clock divided by 32); 9=Div64 (Input clock divided by 64); 10=Div128 (Input clock divided by 128); 11=Div256 (Input clock divided by 256)
